# rCSL_syscfg0_001 register map
Vendor: Texas Instruments
Peripheral module from a debugger description file (folder OMAPL138_C6748).
Registers are 32-bit, read-write, reset 0x0 unless marked. A register's access mark holds for its fields unless they carry their own. Offsets are as the file gives them; lines under a group give offsets from that group; [hi:lo] are bit positions; {n}, {i} and the like mark numbered series; 'fields as' and 'values as' point back to an identical list; <NAME> marks a mode.

## SYSCFG — System config
0x00 REVID — Revision Register
  [31:0] REVID — Revision ID
{0x8+4i} DIEIDR{i} ro (i=0..3) — Die ID Register {i}
  [31:0] DIEID{i} — Internal use only
0x18 DEVIDR0 ro — Device ID Register 0
  [31:0] DEVID0 — Device ID register 0. Read only register that reflects the device ID value.
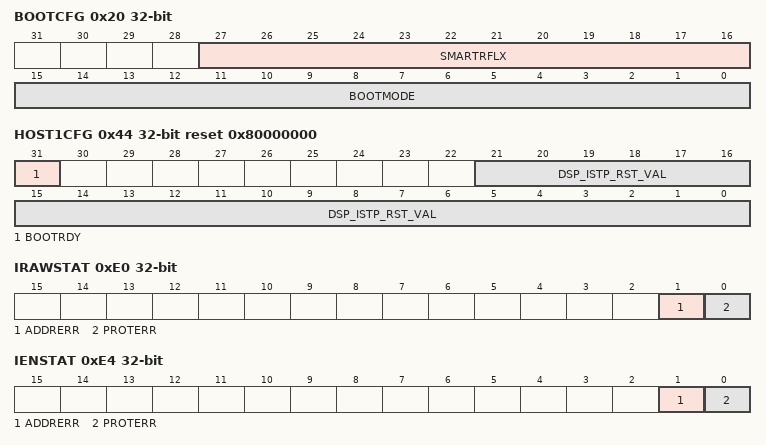
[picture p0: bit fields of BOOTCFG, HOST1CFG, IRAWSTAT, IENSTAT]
0x20 BOOTCFG access not given — Boot Config Register
  [27:16] SMARTRFLX ro — Smart Reflex Trim: These bits are reserved for SmartReflex Type0 Support. Product engineering can blow trim values into these EFUSE bits which can then be used by software to control fine adjustment on an external voltage regulator.
  [15:0] BOOTMODE ro — Boot Mode: This reflects the state of the boot mode pins
0x24 CHIPREVIDR access not given — Chip Revision ID
  [5:0] CHIPREVID ro — Identifies revisions to modules and or Marketing Part Numbers.
0x38 KICK0R ro — Kick 0 Register
  [31:0] KICK0 — The Kick0 register allows writing to unlock the kick0 data. The written data must be 0x83e70b13 to unlock this register. It must be written before the kick1 register. Writing any other value will lock the other MMRs.
0x3C KICK1R ro — Kick 1 Register
  [31:0] KICK1 — The Kick1 register allows writing to unlock the kick1 data and the kicker mechanism to write to other MMRs. The written data must be 0x95a4f1e0 to unlock this register. It must be written before the kick1 register. Writing any other value will lock the other MMRs.
0x40 HOST0CFG access not given — Host 0 Configuration Register
  [31] BOOTRDY rw — ARM boot ready bit allowing ARM to boot.
0x44 HOST1CFG access not given reset 0x80000000 — Host 1 Configuration Register
  [31] BOOTRDY rw — DSP boot ready bit allowing DSP to boot.
  [21:0] DSP_ISTP_RST_VAL rw — DSP boot address vector
0xE0 IRAWSTAT access not given — Interrupt Raw Status/Set Register
  [1] ADDRERR rw — Addressing violation error. Reading this bit field reflects the raw status of the interrupt before enabling. Writing a 1 will set the status. Writing a 0 has not effect.
    0=NOTSET (0 indicates the interrupt is not set. Writing 0 has no effect.); 1=SET (1 indicates the interrupt is set. Writing 1 sets the status.)
  [0] PROTERR rw — Protection violation error. Reading this bit field reflects the raw status of the interrupt before enabling. Writing a 1 will set the status. Writing a 0 has not effect.
    values as ADDRERR
0xE4 IENSTAT access not given — Interrupt Enable Status/Clear Register
  [1] ADDRERR rw — Addressing violation error. Reading this bit field reflects the interrupt enabled status. Writing a 1 will clear the status. Writing a 0 has not effect.
    0=NOTSET (Reading 0 indicates the interrupt is not set. Writing 0 has no effect.); 1=SET_CLEAR (Reading 1 indicates the interrupt is set. Writing 1 clears the status.)
  [0] PROTERR rw — Protection violation error. Reading this bit field reflects the interrupt enabled status. Writing a 1 will clear the status. Writing a 0 has not effect.
    values as ADDRERR
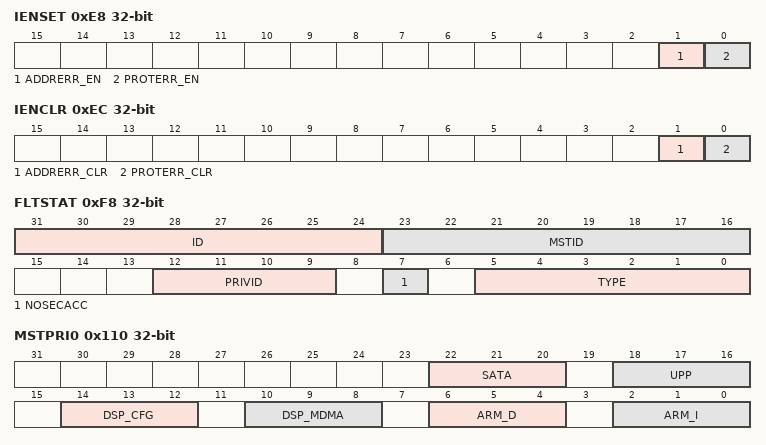
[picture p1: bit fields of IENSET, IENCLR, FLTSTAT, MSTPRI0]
0xE8 IENSET access not given — Interrupt Enable Register
  [1] ADDRERR_EN rw — Addressing violation error. Writing a 1 will enable this interrupt. Writing a 0 has not effect.
    1=SET_EN (Interrupt Enabled.)
  [0] PROTERR_EN rw — Protection violation error. Writing a 1 will enable this interrupt. Writing a 0 has not effect.
    1=SET_EN (Interrupt Enabled.)
0xEC IENCLR access not given — Interrupt Enable Clear Register
  [1] ADDRERR_CLR rw — Addressing violation error. Writing a 1 will clear the enable of this interrupt. Writing a 0 has not effect.
    1=CLEAR_DIS (Writing a 1 clears/disables.)
  [0] PROTERR_CLR rw — Protection violation error. Writing a 1 will clear the enable of this interrupt. Writing a 0 has not effect.
    1=CLEAR_DIS (Writing a 1 clears/disables.)
0xF0 EOI access not given
  [7:0] EOIVECT wo — EOI vector value. Write this with the interrupt distribution value in the chip.
0xF4 FLTADDRR ro — Fault Address Register
  [31:0] FLTADDR — Fault address for the first fault transfer
0xF8 FLTSTAT access not given — Fault Status Register
  [31:24] ID ro — Transfer ID of the first fault transfer
  [23:16] MSTID ro — Master ID of the first fault transfer
  [12:9] PRIVID ro — Priviledge ID of the first fault transfer
  [7] NOSECACC ro — First transfer fault was a non-secure access.
  [5:0] TYPE ro — Fault type of first fault transfer
    0=NOFLT (No transfer fault); 1=USREXE (User execute fault); 2=USRWR (User write fault); 4=USRRD (User read fault); 8=SPREXE (Supervisor execute fault); 22=SPRWR (Supervisor write fault); 50=SPRRD (Supervisor read fault)
0x110 MSTPRI0 access not given (reset mask 0xFF888888) — Master Priority 0 Register
  [22:20] SATA rw — SATA Priority
  [18:16] UPP rw — UPP Priority
  [14:12] DSP_CFG rw — GEM CFG Port priority
  [10:8] DSP_MDMA rw — GEM DMA Port Priority
  [6:4] ARM_D rw — ARM Config Port Priority
  [2:0] ARM_I rw — ARM DMA Port Priority
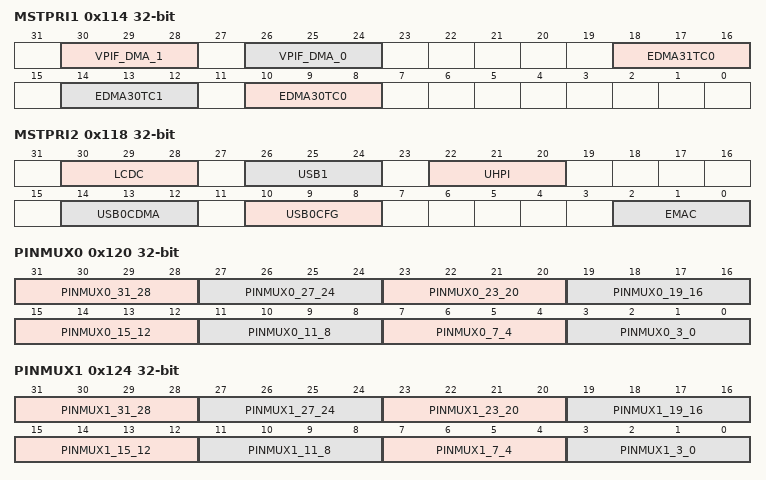
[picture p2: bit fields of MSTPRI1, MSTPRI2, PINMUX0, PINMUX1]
0x114 MSTPRI1 access not given (reset mask 0x88F8FFFF) — Master Priority 1 Register
  [30:28] VPIF_DMA_1 rw — VPID DMA 1 Priority
  [26:24] VPIF_DMA_0 rw — VPID DMA 0 Priority
  [18:16] EDMA31TC0 rw — EDMATC2 Priority
  [14:12] EDMA30TC1 rw — EDMATC1 Priority
  [10:8] EDMA30TC0 rw — EDMATC0 Priority
0x118 MSTPRI2 access not given (reset mask 0x888F88F8) — Master Priority 2 Register
  [30:28] LCDC rw — LCDC Priority
  [26:24] USB1 rw — USB1 Priority
  [22:20] UHPI rw — HPI Priority
  [14:12] USB0CDMA rw — USB0 CDMA Priority
  [10:8] USB0CFG rw — USB0 VBUSP Priority
  [2:0] EMAC rw — EMAC Priority
0x120 PINMUX0
  [31:28] PINMUX0_31_28 — PINMUX0[31:28] mux selection
    0=Default; 2=ALARM; 4=UART2_CTS; 8=GPIO0_8
  [27:24] PINMUX0_27_24 — PINMUX0[27:24] mux selection
    0=Default; 1=AMUTE0; 4=UART2_RTS; 8=GPIO0_9
  [23:20] PINMUX0_23_20 — PINMUX0[23:20] mux selection
    0=Default; 1=AHCLKX0; 2=USB_REFCLKIN; 4=UART1_CTS; 8=GPIO0_10
  [19:16] PINMUX0_19_16 — PINMUX0[19:16] mux selection
    0=Default; 1=AHCLKR0; 4=UART1_RTS; 8=GPIO0_11
  [15:12] PINMUX0_15_12 — PINMUX0[15:12] mux selection
    0=Default; 1=AFSX0; 4=observe0_los; 8=GPIO0_12
  [11:8] PINMUX0_11_8 — PINMUX0[11:8] mux selection
    0=Default; 1=AFSR0; 4=observe0_sync; 8=GPIO0_13
  [7:4] PINMUX0_7_4 — PINMUX0[7:4] mux selection
    0=Default; 1=ACLKX0; 8=GPIO0_14
  [3:0] PINMUX0_3_0 — PINMUX0[3:0] mux selection
    0=Default; 1=ACLKR0; 8=GPIO0_15
0x124 PINMUX1
  [31:28] PINMUX1_31_28 — PINMUX1[31:28] mux selection
    0=Default; 1=AXR0_8; 2=CLKS1; 4=ECAP1; 8=GPIO0_0
  [27:24] PINMUX1_27_24 — PINMUX1[27:24] mux selection
    0=Default; 1=AXR0_9; 2=DX1; 4=observe0_phy_state2; 8=GPIO0_1
  [23:20] PINMUX1_23_20 — PINMUX1[23:20] mux selection
    0=Default; 1=AXR0_10; 2=DR1; 4=observe0_phy_state1; 8=GPIO0_2
  [19:16] PINMUX1_19_16 — PINMUX1[19:16] mux selection
    0=Default; 1=AXR0_11; 2=FSX1; 4=observe0_phy_state0; 8=GPIO0_3
  [15:12] PINMUX1_15_12 — PINMUX1[15:12] mux selection
    0=Default; 1=AXR0_12; 2=FSR1; 4=observe0_phy_ready; 8=GPIO0_4
  [11:8] PINMUX1_11_8 — PINMUX1[11:8] mux selection
    0=Default; 1=AXR0_13; 2=CLKX1; 4=observe0_cominit; 8=GPIO0_5
  [7:4] PINMUX1_7_4 — PINMUX1[7:4] mux selection
    0=Default; 1=AXR0_14; 2=CLKR1; 4=observe0_comwake; 8=GPIO0_6
  [3:0] PINMUX1_3_0 — PINMUX1[3:0] mux selection
    0=Default; 1=AXR0_15; 2=EPWM0TZ0; 4=ECAP2; 8=GPIO0_7
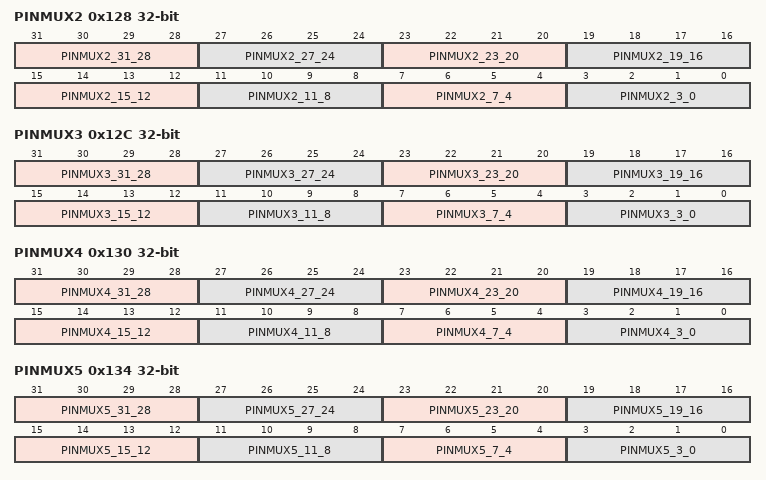
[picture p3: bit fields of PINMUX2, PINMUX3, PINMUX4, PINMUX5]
0x128 PINMUX2
  [31:28] PINMUX2_31_28 — PINMUX2[31:28] mux selection
    0=Default; 1=AXR0_0; 2=ECAP0; 4=GPIO8_7; 8=MII_TXD0
  [27:24] PINMUX2_27_24 — PINMUX2[27:24] mux selection
    0=Default; 1=AXR0_1; 2=DX0; 4=GPIO1_9; 8=MII_TXD1
  [23:20] PINMUX2_23_20 — PINMUX2[23:20] mux selection
    0=Default; 1=AXR0_2; 2=DR0; 4=GPIO1_10; 8=MII_TXD2
  [19:16] PINMUX2_19_16 — PINMUX2[19:16] mux selection
    0=Default; 1=AXR0_3; 2=FSX0; 4=GPIO1_11; 8=MII_TXD3
  [15:12] PINMUX2_15_12 — PINMUX2[15:12] mux selection
    0=Default; 1=AXR0_4; 2=FSR0; 4=GPIO1_12; 8=MII_COL
  [11:8] PINMUX2_11_8 — PINMUX2[11:8] mux selection
    0=Default; 1=AXR0_5; 2=CLKX0; 4=GPIO1_13; 8=MII_TXCLK
  [7:4] PINMUX2_7_4 — PINMUX2[7:4] mux selection
    0=Default; 1=AXR0_6; 2=CLKR0; 4=GPIO1_14; 8=MII_TXEN
  [3:0] PINMUX2_3_0 — PINMUX2[3:0] mux selection
    0=Default; 1=AXR0_7; 2=EPWM1TZ0; 8=GPIO1_15
0x12C PINMUX3
  [31:28] PINMUX3_31_28 — PINMUX3[31:28] mux selection
    0=Default; 1=nSPI0_SCS2; 2=UART0_RTS; 4=GPIO8_1; 8=MII_RXD0
  [27:24] PINMUX3_27_24 — PINMUX3[27:24] mux selection
    0=Default; 1=nSPI0_SCS3; 2=UART0_CTS; 4=GPIO8_2; 8=MII_RXD1
  [23:20] PINMUX3_23_20 — PINMUX3[23:20] mux selection
    0=Default; 1=nSPI0_SCS4; 2=UART0_TXD; 4=GPIO8_3; 8=MII_RXD2
  [19:16] PINMUX3_19_16 — PINMUX3[19:16] mux selection
    0=Default; 1=nSPI0_SCS5; 2=UART0_RXD; 4=GPIO8_4; 8=MII_RXD3
  [15:12] PINMUX3_15_12 — PINMUX3[15:12] mux selection
    0=Default; 1=SPI0_SIMO0; 2=EPWMSYNCO; 4=GPIO8_5; 8=MII_CRS
  [11:8] PINMUX3_11_8 — PINMUX3[11:8] mux selection
    0=Default; 1=SPI0_SOMI0; 2=EPWMSYNCI; 4=GPIO8_6; 8=MII_RXER
  [7:4] PINMUX3_7_4 — PINMUX3[7:4] mux selection
    0=Default; 1=nSPI0_ENA; 2=EPWM0B; 8=MII_RXDV
  [3:0] PINMUX3_3_0 — PINMUX3[3:0] mux selection
    0=Default; 1=SPI0_CLK; 2=EPWM0A; 4=GPIO1_8; 8=MII_RXCLK
0x130 PINMUX4
  [31:28] PINMUX4_31_28 — PINMUX4[31:28] mux selection
    0=Default; 1=nSPI1_SCS2; 2=UART1_TXD; 4=CP_POD; 8=GPIO1_0
  [27:24] PINMUX4_27_24 — PINMUX4[27:24] mux selection
    0=Default; 1=nSPI1_SCS3; 2=UART1_RXD; 4=LED; 8=GPIO1_1
  [23:20] PINMUX4_23_20 — PINMUX4[23:20] mux selection
    0=Default; 1=nSPI1_SCS4; 2=UART2_TXD; 4=I2C1_SDA; 8=GPIO1_2
  [19:16] PINMUX4_19_16 — PINMUX4[19:16] mux selection
    0=Default; 1=nSPI1_SCS5; 2=UART2_RXD; 4=I2C1_SCL; 8=GPIO1_3
  [15:12] PINMUX4_15_12 — PINMUX4[15:12] mux selection
    0=Default; 1=nSPI1_SCS6; 2=I2C0_SDA; 4=TM64P3_OUT12; 8=GPIO1_4
  [11:8] PINMUX4_11_8 — PINMUX4[11:8] mux selection
    0=Default; 1=nSPI1_SCS7; 2=I2C0_SCL; 4=TM64P2_OUT12; 8=GPIO1_5
  [7:4] PINMUX4_7_4 — PINMUX4[7:4] mux selection
    0=Default; 1=nSPI0_SCS0; 2=TM64P1_OUT12; 4=GPIO1_6; 8=MDIO_D
  [3:0] PINMUX4_3_0 — PINMUX4[3:0] mux selection
    0=Default; 1=nSPI0_SCS1; 2=TM64P0_OUT12; 4=GPIO1_7; 8=MDIO_CLK
0x134 PINMUX5
  [31:28] PINMUX5_31_28 — PINMUX5[31:28] mux selection
    0=Default; 1=EMA_BA0; 8=GPIO2_8
  [27:24] PINMUX5_27_24 — PINMUX5[27:24] mux selection
    0=Default; 1=EMA_BA1; 8=GPIO2_9
  [23:20] PINMUX5_23_20 — PINMUX5[23:20] mux selection
    0=Default; 1=SPI1_SIMO0; 8=GPIO2_10
  [19:16] PINMUX5_19_16 — PINMUX5[19:16] mux selection
    0=Default; 1=SPI1_SOMI0; 8=GPIO2_11
  [15:12] PINMUX5_15_12 — PINMUX5[15:12] mux selection
    0=Default; 1=nSPI1_ENA; 8=GPIO2_12
  [11:8] PINMUX5_11_8 — PINMUX5[11:8] mux selection
    0=Default; 1=SPI1_CLK; 8=GPIO2_13
  [7:4] PINMUX5_7_4 — PINMUX5[7:4] mux selection
    0=Default; 1=nSPI1_SCS0; 2=EPWM1B; 8=GPIO2_14
  [3:0] PINMUX5_3_0 — PINMUX5[3:0] mux selection
    0=Default; 1=nSPI1_SCS1; 2=EPWM1A; 8=GPIO2_15
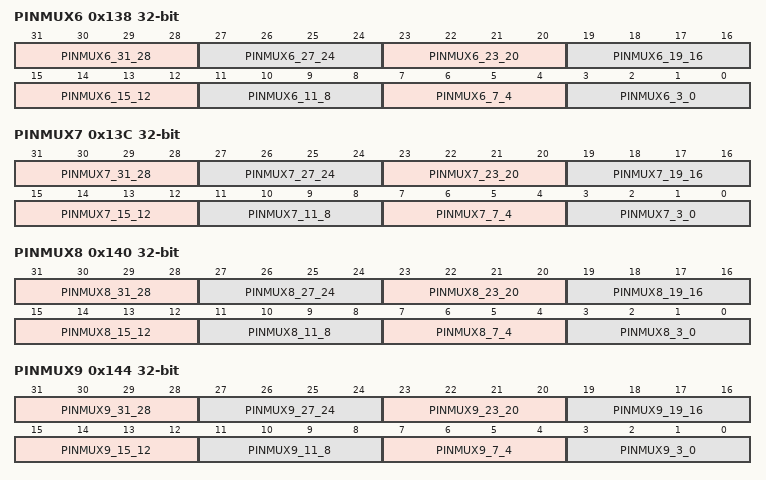
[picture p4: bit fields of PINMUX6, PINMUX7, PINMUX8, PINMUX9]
0x138 PINMUX6
  [31:28] PINMUX6_31_28 — PINMUX6[31:28] mux selection
    0=Default; 1=nEMA_CS0; 8=GPIO2_0
  [27:24] PINMUX6_27_24 — PINMUX6[27:24] mux selection
    0=Default; 1=EMA_WAIT1; 8=GPIO2_1
  [23:20] PINMUX6_23_20 — PINMUX6[23:20] mux selection
    0=Default; 1=nEMA_WE_DQM1; 8=GPIO2_2
  [19:16] PINMUX6_19_16 — PINMUX6[19:16] mux selection
    0=Default; 1=nEMA_WE_DQM0; 8=GPIO2_3
  [15:12] PINMUX6_15_12 — PINMUX6[15:12] mux selection
    0=Default; 1=nEMA_CAS; 8=GPIO2_4
  [11:8] PINMUX6_11_8 — PINMUX6[11:8] mux selection
    0=Default; 1=nEMA_RAS; 8=GPIO2_5
  [7:4] PINMUX6_7_4 — PINMUX6[7:4] mux selection
    0=Default; 1=EMA_SDCKE; 8=GPIO2_6
  [3:0] PINMUX6_3_0 — PINMUX6[3:0] mux selection
    0=Default; 1=EMA_CLK; 8=GPIO2_7
0x13C PINMUX7
  [31:28] PINMUX7_31_28 — PINMUX7[31:28] mux selection
    0=Default; 1=EMA_WAIT0; 8=GPIO3_8
  [27:24] PINMUX7_27_24 — PINMUX7[27:24] mux selection
    0=Default; 1=nEMA_RNW; 8=GPIO3_9
  [23:20] PINMUX7_23_20 — PINMUX7[23:20] mux selection
    0=Default; 1=nEMA_OE; 8=GPIO3_10
  [19:16] PINMUX7_19_16 — PINMUX7[19:16] mux selection
    0=Default; 1=nEMA_WE; 8=GPIO3_11
  [15:12] PINMUX7_15_12 — PINMUX7[15:12] mux selection
    0=Default; 1=nEMA_CS5; 8=GPIO3_12
  [11:8] PINMUX7_11_8 — PINMUX7[11:8] mux selection
    0=Default; 1=nEMA_CS4; 8=GPIO3_13
  [7:4] PINMUX7_7_4 — PINMUX7[7:4] mux selection
    0=Default; 1=nEMA_CS3; 8=GPIO3_14
  [3:0] PINMUX7_3_0 — PINMUX7[3:0] mux selection
    0=Default; 1=nEMA_CS2; 8=GPIO3_15
0x140 PINMUX8
  [31:28] PINMUX8_31_28 — PINMUX8[31:28] mux selection
    0=Default; 1=EMA_D8; 8=GPIO3_0
  [27:24] PINMUX8_27_24 — PINMUX8[27:24] mux selection
    0=Default; 1=EMA_D9; 8=GPIO3_1
  [23:20] PINMUX8_23_20 — PINMUX8[23:20] mux selection
    0=Default; 1=EMA_D10; 8=GPIO3_2
  [19:16] PINMUX8_19_16 — PINMUX8[19:16] mux selection
    0=Default; 1=EMA_D11; 8=GPIO3_3
  [15:12] PINMUX8_15_12 — PINMUX8[15:12] mux selection
    0=Default; 1=EMA_D12; 8=GPIO3_4
  [11:8] PINMUX8_11_8 — PINMUX8[11:8] mux selection
    0=Default; 1=EMA_D13; 8=GPIO3_5
  [7:4] PINMUX8_7_4 — PINMUX8[7:4] mux selection
    0=Default; 1=EMA_D14; 8=GPIO3_6
  [3:0] PINMUX8_3_0 — PINMUX8[3:0] mux selection
    0=Default; 1=EMA_D15; 8=GPIO3_7
0x144 PINMUX9
  [31:28] PINMUX9_31_28 — PINMUX9[31:28] mux selection
    0=Default; 1=EMA_D0; 8=GPIO4_8
  [27:24] PINMUX9_27_24 — PINMUX9[27:24] mux selection
    0=Default; 1=EMA_D1; 8=GPIO4_9
  [23:20] PINMUX9_23_20 — PINMUX9[23:20] mux selection
    0=Default; 1=EMA_D2; 8=GPIO4_10
  [19:16] PINMUX9_19_16 — PINMUX9[19:16] mux selection
    0=Default; 1=EMA_D3; 8=GPIO4_11
  [15:12] PINMUX9_15_12 — PINMUX9[15:12] mux selection
    0=Default; 1=EMA_D4; 8=GPIO4_12
  [11:8] PINMUX9_11_8 — PINMUX9[11:8] mux selection
    0=Default; 1=EMA_D5; 8=GPIO4_13
  [7:4] PINMUX9_7_4 — PINMUX9[7:4] mux selection
    0=Default; 1=EMA_D6; 8=GPIO4_14
  [3:0] PINMUX9_3_0 — PINMUX9[3:0] mux selection
    0=Default; 1=EMA_D7; 8=GPIO4_15
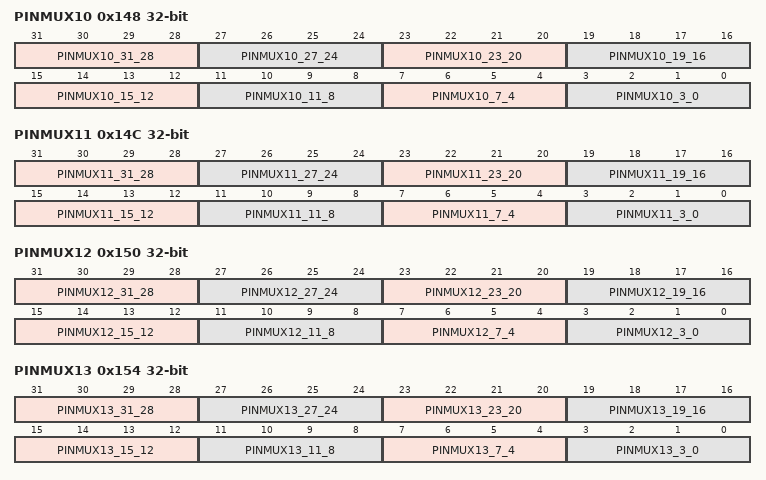
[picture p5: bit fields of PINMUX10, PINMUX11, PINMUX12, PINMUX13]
0x148 PINMUX10
  [31:28] PINMUX10_31_28 — PINMUX10[31:28] mux selection
    0=Default; 1=EMA_A16; 2=MMCSD0_DAT5; 8=GPIO4_0
  [27:24] PINMUX10_27_24 — PINMUX10[27:24] mux selection
    0=Default; 1=EMA_A17; 2=MMCSD0_DAT4; 8=GPIO4_1
  [23:20] PINMUX10_23_20 — PINMUX10[23:20] mux selection
    0=Default; 1=EMA_A18; 2=MMCSD0_DAT3; 8=GPIO4_2
  [19:16] PINMUX10_19_16 — PINMUX10[19:16] mux selection
    0=Default; 1=EMA_A19; 2=MMCSD0_DAT2; 8=GPIO4_3
  [15:12] PINMUX10_15_12 — PINMUX10[15:12] mux selection
    0=Default; 1=EMA_A20; 2=MMCSD0_DAT1; 8=GPIO4_4
  [11:8] PINMUX10_11_8 — PINMUX10[11:8] mux selection
    0=Default; 1=EMA_A21; 2=MMCSD0_DAT0; 8=GPIO4_5
  [7:4] PINMUX10_7_4 — PINMUX10[7:4] mux selection
    0=Default; 1=EMA_A22; 2=MMCSD0_CMD; 8=GPIO4_6
  [3:0] PINMUX10_3_0 — PINMUX10[3:0] mux selection
    0=Default; 1=EMA_A23; 2=MMCSD0_CLK; 8=GPIO4_7
0x14C PINMUX11
  [31:28] PINMUX11_31_28 — PINMUX11[31:28] mux selection
    0=Default; 1=EMA_A8; 8=GPIO5_8
  [27:24] PINMUX11_27_24 — PINMUX11[27:24] mux selection
    0=Default; 1=EMA_A9; 8=GPIO5_9
  [23:20] PINMUX11_23_20 — PINMUX11[23:20] mux selection
    0=Default; 1=EMA_A10; 8=GPIO5_10
  [19:16] PINMUX11_19_16 — PINMUX11[19:16] mux selection
    0=Default; 1=EMA_A11; 8=GPIO5_11
  [15:12] PINMUX11_15_12 — PINMUX11[15:12] mux selection
    0=Default; 1=EMA_A12; 8=GPIO5_12
  [11:8] PINMUX11_11_8 — PINMUX11[11:8] mux selection
    0=Default; 1=EMA_A13; 8=GPIO5_13
  [7:4] PINMUX11_7_4 — PINMUX11[7:4] mux selection
    0=Default; 1=EMA_A14; 2=MMCSD0_DAT7; 8=GPIO5_14
  [3:0] PINMUX11_3_0 — PINMUX11[3:0] mux selection
    0=Default; 1=EMA_A15; 2=MMCSD0_DAT6; 8=GPIO5_15
0x150 PINMUX12
  [31:28] PINMUX12_31_28 — PINMUX12[31:28] mux selection
    0=Default; 1=EMA_A0; 8=GPIO5_0
  [27:24] PINMUX12_27_24 — PINMUX12[27:24] mux selection
    0=Default; 1=EMA_A1; 8=GPIO5_1
  [23:20] PINMUX12_23_20 — PINMUX12[23:20] mux selection
    0=Default; 1=EMA_A2; 8=GPIO5_2
  [19:16] PINMUX12_19_16 — PINMUX12[19:16] mux selection
    0=Default; 1=EMA_A3; 8=GPIO5_3
  [15:12] PINMUX12_15_12 — PINMUX12[15:12] mux selection
    0=Default; 1=EMA_A4; 8=GPIO5_4
  [11:8] PINMUX12_11_8 — PINMUX12[11:8] mux selection
    0=Default; 1=EMA_A5; 8=GPIO5_5
  [7:4] PINMUX12_7_4 — PINMUX12[7:4] mux selection
    0=Default; 1=EMA_A6; 8=GPIO5_6
  [3:0] PINMUX12_3_0 — PINMUX12[3:0] mux selection
    0=Default; 1=EMA_A7; 8=GPIO5_7
0x154 PINMUX13
  [31:28] PINMUX13_31_28 — PINMUX13[31:28] mux selection
    0=Default; 2=UHPI_HRnW; 4=CH1_WAIT; 8=GPIO6_8
  [27:24] PINMUX13_27_24 — PINMUX13[27:24] mux selection
    0=Default; 2=UHPI_HHWIL; 4=CH1_ENABLE; 8=GPIO6_9
  [23:20] PINMUX13_23_20 — PINMUX13[23:20] mux selection
    0=Default; 2=UHPI_HCNTL1; 4=CH1_START; 8=GPIO6_10
  [19:16] PINMUX13_19_16 — PINMUX13[19:16] mux selection
    0=Default; 2=UHPI_HCNTL0; 4=CH1_CLK; 8=GPIO6_11
  [15:12] PINMUX13_15_12 — PINMUX13[15:12] mux selection
    0=Default; 2=nUHPI_HINT; 8=GPIO6_12
  [11:8] PINMUX13_11_8 — PINMUX13[11:8] mux selection
    0=Default; 2=nUHPI_HRDY; 8=GPIO6_13
  [7:4] PINMUX13_7_4 — PINMUX13[7:4] mux selection
    0=Default; 1=OBSCLK0 (OSBCLK0); 2=nUHPI_HDS2; 8=GPIO6_14
  [3:0] PINMUX13_3_0 — PINMUX13[3:0] mux selection
    0=Default; 1=nRESETOUT; 2=nUHPI_HAS; 8=GPIO6_15
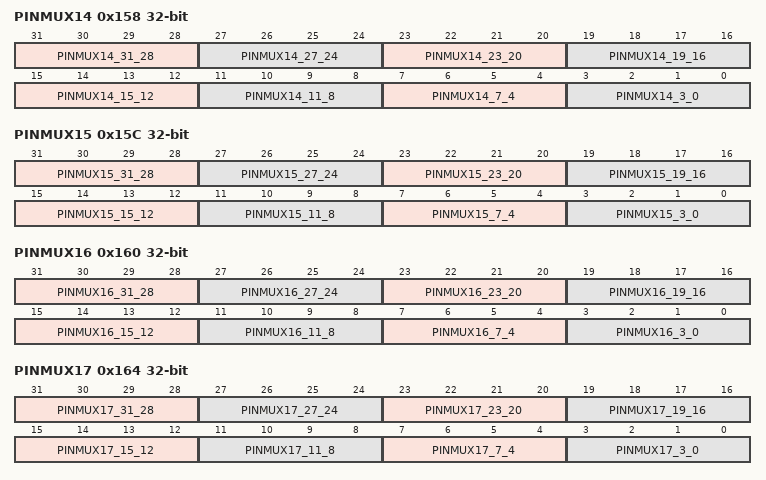
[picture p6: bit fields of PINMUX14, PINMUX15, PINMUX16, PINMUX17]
0x158 PINMUX14
  [31:28] PINMUX14_31_28 — PINMUX14[31:28] mux selection
    0=Default; 1=DIN2; 2=UHPI_HD10; 4=UPP_D10; 8=RMII_RXER
  [27:24] PINMUX14_27_24 — PINMUX14[27:24] mux selection
    0=Default; 1=DIN3; 2=UHPI_HD11; 4=UPP_D11; 8=RMII_RXD0
  [23:20] PINMUX14_23_20 — PINMUX14[23:20] mux selection
    0=Default; 1=DIN4; 2=UHPI_HD12; 4=UPP_D12; 8=RMII_RXD1
  [19:16] PINMUX14_19_16 — PINMUX14[19:16] mux selection
    0=Default; 1=DIN5; 2=UHPI_HD13; 4=UPP_D13; 8=RMII_TXEN
  [15:12] PINMUX14_15_12 — PINMUX14[15:12] mux selection
    0=Default; 1=DIN6; 2=UHPI_HD14; 4=UPP_D14; 8=RMII_TXD0
  [11:8] PINMUX14_11_8 — PINMUX14[11:8] mux selection
    0=Default; 1=DIN7; 2=UHPI_HD15; 4=UPP_D15; 8=RMII_TXD1
  [7:4] PINMUX14_7_4 — PINMUX14[7:4] mux selection
    0=Default; 1=CLKIN1; 2=nUHPI_HDS1; 8=GPIO6_6 (GPIO06_6)
  [3:0] PINMUX14_3_0 — PINMUX14[3:0] mux selection
    0=Default; 1=CLKIN0; 2=nUHPI_HCS; 8=GPIO6_7
0x15C PINMUX15
  [31:28] PINMUX15_31_28 — PINMUX15[31:28] mux selection
    0=Default; 1=DIN10; 2=UHPI_HD2; 4=UPP_D2
  [27:24] PINMUX15_27_24 — PINMUX15[27:24] mux selection
    0=Default; 1=DIN11; 2=UHPI_HD3; 4=UPP_D3
  [23:20] PINMUX15_23_20 — PINMUX15[23:20] mux selection
    0=Default; 1=DIN12; 2=UHPI_HD4; 4=UPP_D4
  [19:16] PINMUX15_19_16 — PINMUX15[19:16] mux selection
    0=Default; 1=DIN13_FIELD; 2=UHPI_HD5; 4=UPP_D5
  [15:12] PINMUX15_15_12 — PINMUX15[15:12] mux selection
    0=Default; 1=DIN14_HSYNC; 2=UHPI_HD6; 4=UPP_D6
  [11:8] PINMUX15_11_8 — PINMUX15[11:8] mux selection
    0=Default; 1=DIN15_VSYNC; 2=UHPI_HD7; 4=UPP_D7
  [7:4] PINMUX15_7_4 — PINMUX15[7:4] mux selection
    0=Default; 1=DIN0; 2=UHPI_HD8; 4=UPP_D8; 8=RMII_CRS_DV
  [3:0] PINMUX15_3_0 — PINMUX15[3:0] mux selection
    0=Default; 1=DIN1; 2=UHPI_HD9; 4=UPP_D9; 8=RMII_MHZ_50_CLK
0x160 PINMUX16
  [31:28] PINMUX16_31_28 — PINMUX16[31:28] mux selection
    0=Default; 1=DOUT2; 2=LCD_D2; 4=UPP_XD10; 8=GPIO7_10
  [27:24] PINMUX16_27_24 — PINMUX16[27:24] mux selection
    0=Default; 1=DOUT3; 2=LCD_D3; 4=UPP_XD11; 8=GPIO7_11
  [23:20] PINMUX16_23_20 — PINMUX16[23:20] mux selection
    0=Default; 1=DOUT4; 2=LCD_D4; 4=UPP_XD12; 8=GPIO7_12
  [19:16] PINMUX16_19_16 — PINMUX16[19:16] mux selection
    0=Default; 1=DOUT5; 2=LCD_D5; 4=UPP_XD13; 8=GPIO7_13
  [15:12] PINMUX16_15_12 — PINMUX16[15:12] mux selection
    0=Default; 1=DOUT6; 2=LCD_D6; 4=UPP_XD14; 8=GPIO7_14
  [11:8] PINMUX16_11_8 — PINMUX16[11:8] mux selection
    0=Default; 1=DOUT7; 2=LCD_D7; 4=UPP_XD15; 8=GPIO7_15
  [7:4] PINMUX16_7_4 — PINMUX16[7:4] mux selection
    0=Default; 1=DIN8; 2=UHPI_HD0; 4=UPP_D0; 8=GPIO6_5
  [3:0] PINMUX16_3_0 — PINMUX16[3:0] mux selection
    0=Default; 1=DIN9; 2=UHPI_HD1; 4=UPP_D1
0x164 PINMUX17
  [31:28] PINMUX17_31_28 — PINMUX17[31:28] mux selection
    0=Default; 1=DOUT10; 2=LCD_D10; 4=UPP_XD2; 8=GPIO7_2
  [27:24] PINMUX17_27_24 — PINMUX17[27:24] mux selection
    0=Default; 1=DOUT11; 2=LCD_D11; 4=UPP_XD3; 8=GPIO7_3
  [23:20] PINMUX17_23_20 — PINMUX17[23:20] mux selection
    0=Default; 1=DOUT12; 2=LCD_D12; 4=UPP_XD4; 8=GPIO7_4
  [19:16] PINMUX17_19_16 — PINMUX17[19:16] mux selection
    0=Default; 1=DOUT13; 2=LCD_D13; 4=UPP_XD5; 8=GPIO7_5
  [15:12] PINMUX17_15_12 — PINMUX17[15:12] mux selection
    0=Default; 1=DOUT14; 2=LCD_D14; 4=UPP_XD6; 8=GPIO7_6
  [11:8] PINMUX17_11_8 — PINMUX17[11:8] mux selection
    0=Default; 1=DOUT15; 2=LCD_D15; 4=UPP_XD7; 8=GPIO7_7
  [7:4] PINMUX17_7_4 — PINMUX17[7:4] mux selection
    0=Default; 1=DOUT0; 2=LCD_D0; 4=UPP_XD8; 8=GPIO7_8
  [3:0] PINMUX17_3_0 — PINMUX17[3:0] mux selection
    0=Default; 1=DOUT1; 2=LCD_D1; 4=UPP_XD9; 8=GPIO7_9
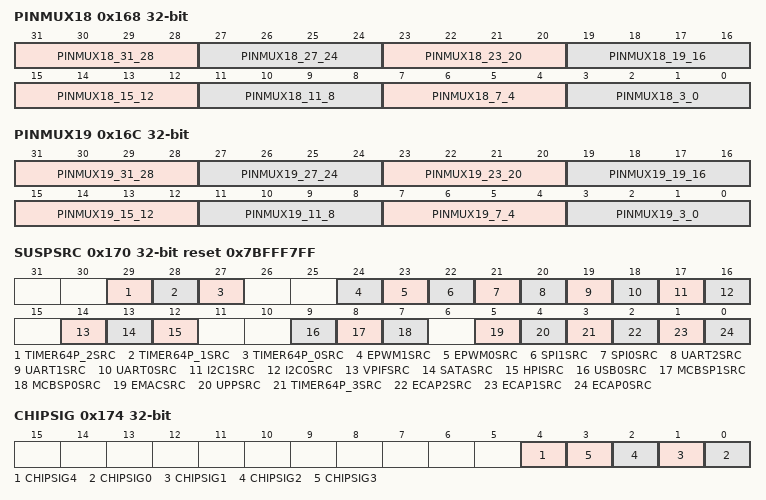
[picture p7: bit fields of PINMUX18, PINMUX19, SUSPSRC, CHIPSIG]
0x168 PINMUX18
  [31:28] PINMUX18_31_28 — PINMUX18[31:28] mux selection
    0=Default; 1=MMCSD1_DAT6; 2=LCD_MCLK; 8=GPIO8_10
  [27:24] PINMUX18_27_24 — PINMUX18[27:24] mux selection
    0=Default; 1=MMCSD1_DAT7; 2=LCD_PCLK; 8=GPIO8_11
  [23:20] PINMUX18_23_20 — PINMUX18[23:20] mux selection
    0=Default; 4=CH0_WAIT; 8=GPIO8_12
  [19:16] PINMUX18_19_16 — PINMUX18[19:16] mux selection
    0=Default; 2=MMCSD1_CMD; 4=CH0_ENABLE; 8=GPIO8_13
  [15:12] PINMUX18_15_12 — PINMUX18[15:12] mux selection
    0=Default; 2=MMCSD1_CLK; 4=CH0_START; 8=GPIO8_14
  [11:8] PINMUX18_11_8 — PINMUX18[11:8] mux selection
    0=Default; 2=MMCSD1_DAT0; 4=CH0_CLK; 8=GPIO8_15
  [7:4] PINMUX18_7_4 — PINMUX18[7:4] mux selection
    0=Default; 1=DOUT8; 2=LCD_D8; 4=UPP_XD0; 8=GPIO7_0
  [3:0] PINMUX18_3_0 — PINMUX18[3:0] mux selection
    0=Default; 1=DOUT9; 2=LCD_D9; 4=UPP_XD1; 8=GPIO7_1
0x16C PINMUX19
  [31:28] PINMUX19_31_28 — PINMUX19[31:28] mux selection
    0=Default; 1=RTCK; 8=GPIO8_0
  [27:24] PINMUX19_27_24 — PINMUX19[27:24] mux selection
    0=Default; 2=nLCD_AC_ENB_CS; 8=GPIO6_0
  [23:20] PINMUX19_23_20 — PINMUX19[23:20] mux selection
    0=Default; 1=CLKO3; 8=GPIO6_1
  [19:16] PINMUX19_19_16 — PINMUX19[19:16] mux selection
    0=Default; 1=CLKIN3; 2=MMCSD1_DAT1; 8=GPIO6_2
  [15:12] PINMUX19_15_12 — PINMUX19[15:12] mux selection
    0=Default; 1=CLKO2; 2=MMCSD1_DAT2; 8=GPIO6_3
  [11:8] PINMUX19_11_8 — PINMUX19[11:8] mux selection
    0=Default; 1=CLKIN2; 2=MMCSD1_DAT3; 8=GPIO6_4
  [7:4] PINMUX19_7_4 — PINMUX19[7:4] mux selection
    0=Default; 1=MMCSD1_DAT4; 2=LCD_VSYNC; 8=GPIO8_8
  [3:0] PINMUX19_3_0 — PINMUX19[3:0] mux selection
    0=Default; 1=MMCSD1_DAT5; 2=LCD_HSYNC; 8=GPIO8_9
0x170 SUSPSRC access not given reset 0x7BFFF7FF — Suspend Source Register
  [all] fields
    0=ARM (ARM is the source of the emulation suspend); 1=DSP (DSP is the source of the emulation suspend)
  [29] TIMER64P_2SRC rw — Timer2 64 Emulation Suspend Source
  [28] TIMER64P_1SRC rw — Timer1 64 Emulation Suspend Source
  [27] TIMER64P_0SRC rw — Timer0 64 Emulation Suspend Source
  [24] EPWM1SRC rw — EPWM1 Emulation Suspend Source
  [23] EPWM0SRC rw — EPWM0 Emulation Suspend Source
  [22] SPI1SRC rw — SPI1 Emulation Suspend Source
  [21] SPI0SRC rw — SPI0 Emulation Suspend Source
  [20] UART2SRC rw — UART2 Emulation Suspend Source
  [19] UART1SRC rw — UART1 Emulation Suspend Source
  [18] UART0SRC rw — UART0 Emulation Suspend Source
  [17] I2C1SRC rw — I2C1 Emulation Suspend Source
  [16] I2C0SRC rw — I2C0 Emulation Suspend Source
  [14] VPIFSRC rw — VPIF Emulation Suspend Source
  [13] SATASRC rw — SATA Emulation Suspend Source
  [12] HPISRC rw — HPI Emulation Suspend Source
  [9] USB0SRC rw — USB0 Emulation Suspend Source
  [8] MCBSP1SRC rw — McBSP1 Emulation Suspend Source
  [7] MCBSP0SRC rw — McBSP0 Emulation Suspend Source
  [5] EMACSRC rw — EMAC Emulation Suspend Source
  [4] UPPSRC rw — UPP Emulation Suspend Source
  [3] TIMER64P_3SRC rw — TIMER64P3 Emulation Suspend Source
  [2] ECAP2SRC rw — ECAP2 Emulation Suspend Source
  [1] ECAP1SRC rw — ECAP1 Emulation Suspend Source
  [0] ECAP0SRC rw — ECAP0 Emulation Suspend Source
0x174 CHIPSIG access not given — Chip Signal Register
  [all] fields
    0=NOTHING (Does nothing); 1=ASSERT (Asserts interrupt)
  [4] CHIPSIG4 rw — Asserts GEM NMI Interrupt
  [n] CHIPSIG{n} rw (n=0..3) — Asserts GEM Interrupt CHIPSIG{n}
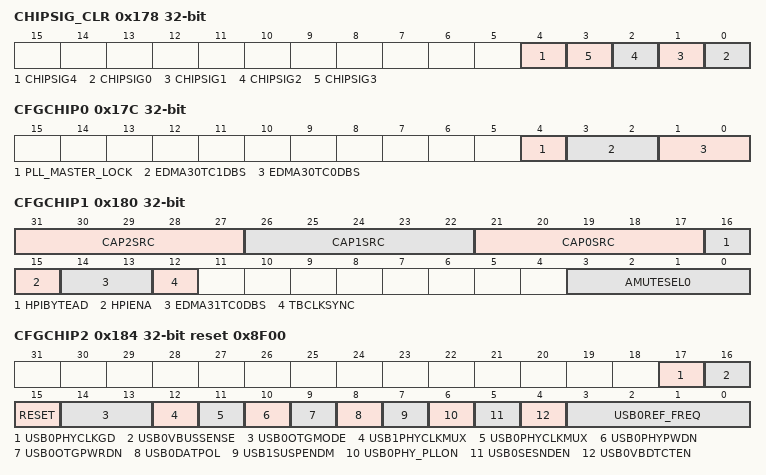
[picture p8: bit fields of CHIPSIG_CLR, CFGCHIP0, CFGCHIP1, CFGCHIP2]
0x178 CHIPSIG_CLR access not given — Chip Signal Clear Register
  [all] fields
    0=NOTHING (Does nothing); 1=CLEAR (Clears interrupt)
  [4] CHIPSIG4 rw — Clears GEM NMI Interrupt
  [n] CHIPSIG{n} rw (n=0..3) — Clears GEM Interrupt CHIPSIG{n}
0x17C CFGCHIP0 access not given — Chip Configuration 0 Register
  [4] PLL_MASTER_LOCK rw — Lock the PLL MMRs
    0=FREE (PLLCTRL MMR are freely accessible as normal); 1=LOCK (Lock down all PLLCTRL MMR)
  [3:2] EDMA30TC1DBS rw — TC1 Default Burst Size
    0=16byte; 1=32byte; 2=64byte
  [1:0] EDMA30TC0DBS rw — TC0 Default Burst Size
    0=16byte; 1=32byte; 2=64byte
0x180 CFGCHIP1 access not given — Chip Configuration 1 Register
  [31:27] CAP2SRC rw — Selects the eCAP2 module event input
    0=ECAP2 (eCAP2 Pin input); 1=MCASP0_TXDMA (McASP0 TX DMA Event); 2=MCASP0_RXDMA (McASP0 RX DMA Event); 3=MCASP1_TXDMA (McASP1 TX DMA Event); 4=MCASP1_RXDMA (McASP1 RX DMA Event); 5=MCASP2_TXDMA (McASP2 TX DMA Event); 6=MCASP2_RXDMA (McASP2 RX DMA Event); 7=EMAC_C0_RXTHPLSEINT (EMAC C0 RX Th. Pulse Int); 8=EMAC_C0_RXPLSEINT (EMAC C0 RX Pulse Int); 9=EMAC_C0_TXPLSEINT (EMAC C0 TX Pulse Int); 16=EMAC_C0_MISCINT; 17=EMAC_C1_RXTHPLSEINT (EMAC C1 RX Th. Pulse Int); 18=EMAC_C1_RXPLSEINT (EMAC C1 RX Pulse Int); 19=EMAC_C1_TXPLSEINT (EMAC C1 TX Pulse Int); 20=EMAC_C1_MISCINT; 21=EMAC_C2_RXTHPLSEINT (EMAC C2 RX Th. Pulse Int); 22=EMAC_C2_RXPLSEINT (EMAC C2 RX Pulse Int); 23=EMAC_C2_TXPLSEINT (EMAC C2 TX Pulse Int); 24=EMAC_C2_MISCINT
  [26:22] CAP1SRC rw — Selects the eCAP1 module event input
    0=ECAP1 (eCAP1 Pin input); 1=MCASP0_TXDMA (McASP0 TX DMA Event); 2=MCASP0_RXDMA (McASP0 RX DMA Event); 3=MCASP1_TXDMA (McASP1 TX DMA Event); 4=MCASP1_RXDMA (McASP1 RX DMA Event); 5=MCASP2_TXDMA (McASP2 TX DMA Event); 6=MCASP2_RXDMA (McASP2 RX DMA Event); 7=EMAC_C0_RXTHPLSEINT (EMAC C0 RX Th. Pulse Int); 8=EMAC_C0_RXPLSEINT (EMAC C0 RX Pulse Int); 9=EMAC_C0_TXPLSEINT (EMAC C0 TX Pulse Int); 16=EMAC_C0_MISCINT; 17=EMAC_C1_RXTHPLSEINT (EMAC C1 RX Th. Pulse Int); 18=EMAC_C1_RXPLSEINT (EMAC C1 RX Pulse Int); 19=EMAC_C1_TXPLSEINT (EMAC C1 TX Pulse Int); 20=EMAC_C1_MISCINT; 21=EMAC_C2_RXTHPLSEINT (EMAC C2 RX Th. Pulse Int); 22=EMAC_C2_RXPLSEINT (EMAC C2 RX Pulse Int); 23=EMAC_C2_TXPLSEINT (EMAC C2 TX Pulse Int); 24=EMAC_C2_MISCINT
  [21:17] CAP0SRC rw — Selects the eCAP0 module event input
    0=ECAP0 (eCAP0 Pin input); 1=MCASP0_TXDMA (McASP0 TX DMA Event); 2=MCASP0_RXDMA (McASP0 RX DMA Event); 3=MCASP1_TXDMA (McASP1 TX DMA Event); 4=MCASP1_RXDMA (McASP1 RX DMA Event); 5=MCASP2_TXDMA (McASP2 TX DMA Event); 6=MCASP2_RXDMA (McASP2 RX DMA Event); 7=EMAC_C0_RXTHPLSEINT (EMAC C0 RX Th. Pulse Int); 8=EMAC_C0_RXPLSEINT (EMAC C0 RX Pulse Int); 9=EMAC_C0_TXPLSEINT (EMAC C0 TX Pulse Int); 16=EMAC_C0_MISCINT; 17=EMAC_C1_RXTHPLSEINT (EMAC C1 RX Th. Pulse Int); 18=EMAC_C1_RXPLSEINT (EMAC C1 RX Pulse Int); 19=EMAC_C1_TXPLSEINT (EMAC C1 TX Pulse Int); 20=EMAC_C1_MISCINT; 21=EMAC_C2_RXTHPLSEINT (EMAC C2 RX Th. Pulse Int); 22=EMAC_C2_RXPLSEINT (EMAC C2 RX Pulse Int); 23=EMAC_C2_TXPLSEINT (EMAC C2 TX Pulse Int); 24=EMAC_C2_MISCINT
  [16] HPIBYTEAD rw — HPI Byte/Word Address Mode select
    0=WORDADDR (Host address is a word address); 1=BYTEADDR (Host address is a byte address)
  [15] HPIENA rw — HPI Enable Bit
    0=DISABLE (HPI disabled); 1=ENABLE (HPI enabled)
  [14:13] EDMA31TC0DBS rw — TC2 Default Burst Size
    0=16byte; 1=32byte; 2=64byte
  [12] TBCLKSYNC rw — Clears the latched GPIO interrupt for AMUTEIN of McASP1 when 1.
    0=STOP (TBCLK is stopped); 1=ENABLE (TBCLK is aligned to first rising edge)
  [3:0] AMUTESEL0 rw — Selects the source of McASP0 AMUTEIN signal
    0=LOW (Drive Low); {v}=GPIO_B{v-1} (GPIO Int from Bank {v-1}) (v=1..8)
0x184 CFGCHIP2 access not given reset 0x8F00 (reset mask 0xFFFF9FFF) — Chip Configuration 2 Register
  [17] USB0PHYCLKGD ro — Reports status of USB 2.0 PHY. Clock is present, power is good, pll locked
  [16] USB0VBUSSENSE ro — Reports status of USB 2.0 PHY VBUS detection
  [15] RESET rw — Places USB 2.0 PHY in reset
  [14:13] USB0OTGMODE rw — what USB2.0 PHY comparators are used to drive
    0=PHY (No override. PHY drive signals to controller based on its comparators for VBUS and ID pins); 1=USB_HOST (Override phy values to force USB Host Operation); 2=USB_DEVICE (Override phy values to force USB Device Operation); 3=USB_HOST_LOW (Ovverride phy values to force USB Host Operation with VBUS low)
  [12] USB1PHYCLKMUX rw — Controls USB1 PHY reference clock input mux
    0=USBCLK (USB 1.1 PHY reference clock source by output of USB2.0 PHY); 1=EXTCLK (USB 1.1 PHY reference clock externally generated)
  [11] USB0PHYCLKMUX rw — Controls USB2 PHY reference clock input mux
    0=INTCLK (USB 2.0 PHY reference clock internally generated); 1=EXTCLK (USB 2.0 PHY reference clock externally generated)
  [10] USB0PHYPWDN rw — Power down USB 2.0 PHY
  [9] USB0OTGPWRDN rw — Power down USB 2.0 OTG Subsystem
  [8] USB0DATPOL rw — Select data polarity of USB 2.0 OTG subsystem
  [7] USB1SUSPENDM rw — Controls USB1 Suspend mode
    0=DISABLED (Needs to be '0' whenever USB1.1 phys is unpowered); 1=ENABLED (Enable its PHY)
  [6] USB0PHY_PLLON rw — Turn on/off USB PLL
  [5] USB0SESNDEN rw — Turns on Session End comparator
  [4] USB0VBDTCTEN rw — Turns on VBUS line comparators
  [3:0] USB0REF_FREQ rw — Configure USB PHY for different reference clock input frequencies
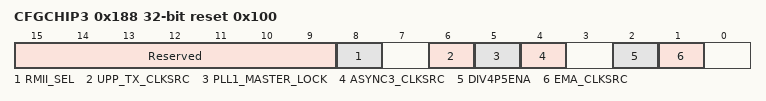
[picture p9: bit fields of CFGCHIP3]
0x188 CFGCHIP3 access not given reset 0x100 — Chip Configuration 3 Register
  [15:9] Reserved — (access N)
  [8] RMII_SEL rw — EMAC MII and RMII Select
    0=MII (MII mode); 1=RMII (RMII mode)
  [6] UPP_TX_CLKSRC rw — UPP 2x Transmit Clock Source
    0=ASYNC3 (source from ASYNC3); 1=TXCLK (source from external signal 2xTXCLK)
  [5] PLL1_MASTER_LOCK rw — Lock the PLL MMR
    0=FREE (PLL MMR freely accessible); 1=LOCK (Lock down all PLL MMR)
  [4] ASYNC3_CLKSRC rw — ASYNC3 clock source
    0=PLL0 (sourced by PLL0 SYSCLK2); 1=PLL1 (sourced by PLL1 SYSCLK2)
  [2] DIV4P5ENA rw — Controls the fixed /4.5 divider added to the PLL controller
    0=DISABLE (Divide by 4.5 is Disabled); 1=ENABLE (Divide by 4.5 is Enabled)
  [1] EMA_CLKSRC rw — Clock source for EMIFA clock domain
    0=PLLCTRL_SYSCLK3 (Clock driven by PLLCTRL SYSCLK3); 1=4P5_PLL (Clock driven by 4.5 PLL output)
0x18C CFGCHIP4 access not given reset 0x100 — Chip Configuration 4 Register
  [0] AMUTECLR0 rw — Clears the latched GPIO interrupt for AMUTEIN of McASP2 when 1.
    1=CLEAR (Clears interrupt)
